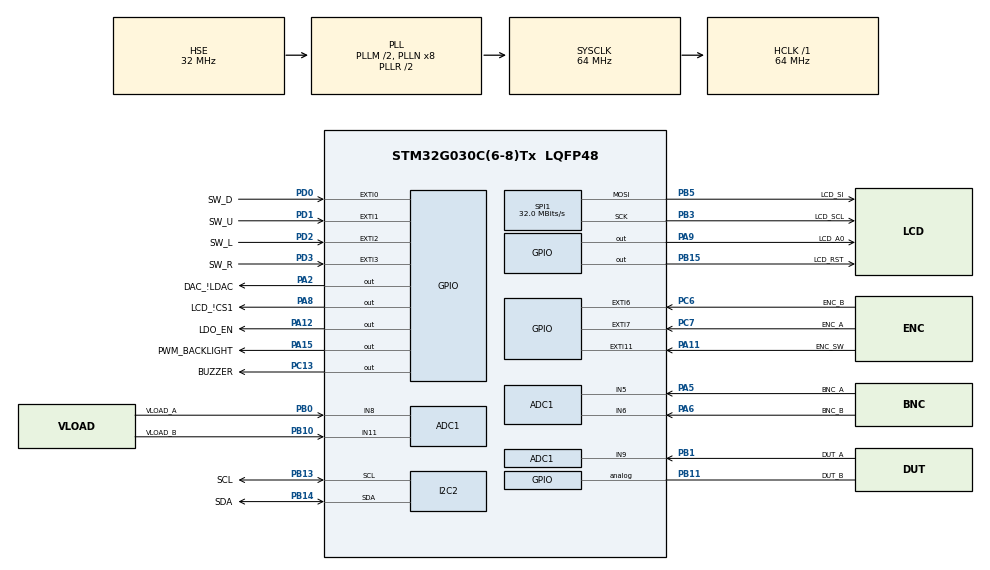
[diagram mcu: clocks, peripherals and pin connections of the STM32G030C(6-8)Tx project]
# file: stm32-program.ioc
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ADC1.Channel-1\#ChannelRegularConversion=ADC_CHANNEL_5
ADC1.ContinuousConvMode=ENABLE
ADC1.NbrOfConversionFlag=1
ADC1.Rank-1\#ChannelRegularConversion=1
ADC1.SamplingTime-1\#ChannelRegularConversion=ADC_SAMPLINGTIME_COMMON_1
ADC1.SelectedChannel=ADC_CHANNEL_5|ADC_CHANNEL_6|ADC_CHANNEL_8|ADC_CHANNEL_9|ADC_CHANNEL_11
ADC1.master=1
I2C2.Timing=0x10B17DB5
Mcu.Family=STM32G0
Mcu.Name=STM32G030C(6-8)Tx
Mcu.Package=LQFP48
NVIC.ADC1_IRQn=true\:0\:0\:false\:false\:true\:true\:true\:true
NVIC.EXTI0_1_IRQn=true\:0\:0\:false\:false\:true\:true\:true\:true
NVIC.EXTI2_3_IRQn=true\:0\:0\:false\:false\:true\:true\:true\:true
NVIC.EXTI4_15_IRQn=true\:0\:0\:false\:false\:true\:true\:true\:true
NVIC.I2C2_IRQn=true\:0\:0\:false\:false\:true\:true\:true\:true
NVIC.SPI1_IRQn=true\:0\:0\:false\:false\:true\:true\:true\:true
PA11\ [PA9].GPIO_Label=ENC_SW
PA11\ [PA9].GPIO_ModeDefaultEXTI=GPIO_MODE_IT_FALLING
PA11\ [PA9].GPIO_PuPd=GPIO_PULLUP
PA11\ [PA9].Signal=GPXTI11
PA12\ [PA10].GPIO_Label=LDO_EN
PA12\ [PA10].Signal=GPIO_Output
PA13.GPIO_Label=SWDIO
PA13.Mode=Serial_Wire
PA13.Signal=SYS_SWDIO
PA14-BOOT0.GPIO_Label=SWCLK
PA14-BOOT0.Mode=Serial_Wire
PA14-BOOT0.Signal=SYS_SWCLK
PA15.GPIO_Label=PWM_BACKLIGHT
PA15.Signal=GPIO_Output
PA2.GPIO_Label=DAC_\!LDAC
PA2.Signal=GPIO_Output
PA5.GPIO_Label=BNC_A
PA5.Signal=SharedAnalog_PA5
PA6.GPIO_Label=BNC_B
PA6.Signal=SharedAnalog_PA6
PA8.GPIO_Label=LCD_\!CS1
PA8.Signal=GPIO_Output
PA9.GPIO_Label=LCD_A0
PA9.Signal=GPIO_Output
PB0.GPIO_Label=VLOAD_A
PB0.Signal=SharedAnalog_PB0
PB1.GPIO_Label=DUT_A
PB1.Signal=SharedAnalog_PB1
PB10.GPIO_Label=VLOAD_B
PB10.Signal=SharedAnalog_PB10
PB11.GPIO_Label=DUT_B
PB11.Signal=SharedAnalog_PB11
PB13.GPIO_Label=SCL
PB13.Mode=I2C
PB13.Signal=I2C2_SCL
PB14.GPIO_Label=SDA
PB14.Mode=I2C
PB14.Signal=I2C2_SDA
PB15.GPIO_Label=LCD_RST
PB15.Signal=GPIO_Output
PB3.GPIO_Label=LCD_SCL
PB3.Mode=TX_Only_Simplex_Unidirect_Master
PB3.Signal=SPI1_SCK
PB5.GPIO_Label=LCD_SI
PB5.Mode=TX_Only_Simplex_Unidirect_Master
PB5.Signal=SPI1_MOSI
PC13.GPIO_Label=BUZZER
PC13.Signal=GPIO_Output
PC6.GPIO_Label=ENC_B
PC6.GPIO_ModeDefaultEXTI=GPIO_MODE_IT_FALLING
PC6.Signal=GPXTI6
PC7.GPIO_Label=ENC_A
PC7.GPIO_ModeDefaultEXTI=GPIO_MODE_IT_FALLING
PC7.Signal=GPXTI7
PD0.GPIO_Label=SW_D
PD0.GPIO_ModeDefaultEXTI=GPIO_MODE_IT_FALLING
PD0.GPIO_PuPd=GPIO_PULLUP
PD0.Signal=GPXTI0
PD1.GPIO_Label=SW_U
PD1.GPIO_ModeDefaultEXTI=GPIO_MODE_IT_FALLING
PD1.GPIO_PuPd=GPIO_PULLUP
PD1.Signal=GPXTI1
PD2.GPIO_Label=SW_L
PD2.GPIO_ModeDefaultEXTI=GPIO_MODE_IT_FALLING
PD2.GPIO_PuPd=GPIO_PULLUP
PD2.Signal=GPXTI2
PD3.GPIO_Label=SW_R
PD3.GPIO_ModeDefaultEXTI=GPIO_MODE_IT_FALLING
PD3.GPIO_PuPd=GPIO_PULLUP
PD3.Signal=GPXTI3
PF0-OSC_IN\ (PF0).GPIO_Label=OSC_IN
PF0-OSC_IN\ (PF0).Mode=HSE-External-Oscillator
PF0-OSC_IN\ (PF0).Signal=RCC_OSC_IN
PF1-OSC_OUT\ (PF1).GPIO_Label=OSC_OUT
PF1-OSC_OUT\ (PF1).Mode=HSE-External-Oscillator
PF1-OSC_OUT\ (PF1).Signal=RCC_OSC_OUT
ProjectManager.HeapSize=0x200
ProjectManager.StackSize=0x400
ProjectManager.TargetToolchain=STM32CubeIDE
RCC.ADCFreq_Value=64000000
RCC.AHBFreq_Value=64000000
RCC.CortexFreq_Value=64000000
RCC.EXTERNAL_CLOCK_VALUE=12288000
RCC.EnbaleCSS=true
RCC.HCLKFreq_Value=64000000
RCC.HSE_VALUE=32000000
RCC.HSI_VALUE=16000000
RCC.LSE_VALUE=32768
RCC.PLLM=RCC_PLLM_DIV2
RCC.PLLSourceVirtual=RCC_PLLSOURCE_HSE
RCC.SYSCLKFreq_VALUE=64000000
RCC.SYSCLKSource=RCC_SYSCLKSOURCE_PLLCLK
RCC.VCOOutputFreq_Value=128000000
SH.SharedAnalog_PA5.0=GPIO_Analog
SH.SharedAnalog_PA5.1=ADC1_IN5,IN5
SH.SharedAnalog_PA6.0=GPIO_Analog
SH.SharedAnalog_PA6.1=ADC1_IN6,IN6
SH.SharedAnalog_PB0.0=GPIO_Analog
SH.SharedAnalog_PB0.1=ADC1_IN8,IN8
SH.SharedAnalog_PB1.0=GPIO_Analog
SH.SharedAnalog_PB1.1=ADC1_IN9,IN9
SH.SharedAnalog_PB10.0=GPIO_Analog
SH.SharedAnalog_PB10.1=ADC1_IN11,IN11
SH.SharedAnalog_PB11.0=GPIO_Analog
SH.SharedAnalog_PB11.1=ADC1_IN15
SPI1.CalculateBaudRate=32.0 MBits/s
SPI1.Direction=SPI_DIRECTION_2LINES
SPI1.Mode=SPI_MODE_MASTER
SPI1.VirtualType=VM_MASTER
board=custom

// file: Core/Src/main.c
/* USER CODE BEGIN Header */
/**
  ******************************************************************************
  * @file           : main.c
  * @brief          : Main program body
  ******************************************************************************
  * @attention
  *
  * Copyright (c) 2025 STMicroelectronics.
  * All rights reserved.
  *
  * This software is licensed under terms that can be found in the LICENSE file
  * in the root directory of this software component.
  * If no LICENSE file comes with this software, it is provided AS-IS.
  *
  ******************************************************************************
  */
/* USER CODE END Header */
#include "main.h"

ADC_HandleTypeDef hadc1;

I2C_HandleTypeDef hi2c2;

SPI_HandleTypeDef hspi1;

void SystemClock_Config(void);
static void MX_GPIO_Init(void);
static void MX_I2C2_Init(void);
static void MX_ADC1_Init(void);
static void MX_SPI1_Init(void);

int main(void)
{

  /* MCU Configuration--------------------------------------------------------*/

  /* Reset of all peripherals, Initializes the Flash interface and the Systick. */
  HAL_Init();

  /* Configure the system clock */
  SystemClock_Config();

  /* Initialize all configured peripherals */
  MX_GPIO_Init();
  MX_I2C2_Init();
  MX_ADC1_Init();
  MX_SPI1_Init();

  /* Infinite loop */
  while (1)
  {

  }
}

void SystemClock_Config(void)
{
  RCC_OscInitTypeDef RCC_OscInitStruct = {0};
  RCC_ClkInitTypeDef RCC_ClkInitStruct = {0};

  /** Configure the main internal regulator output voltage
  */
  HAL_PWREx_ControlVoltageScaling(PWR_REGULATOR_VOLTAGE_SCALE1);

  /** Initializes the RCC Oscillators according to the specified parameters
  * in the RCC_OscInitTypeDef structure.
  */
  RCC_OscInitStruct.OscillatorType = RCC_OSCILLATORTYPE_HSE;
  RCC_OscInitStruct.HSEState = RCC_HSE_ON;
  RCC_OscInitStruct.PLL.PLLState = RCC_PLL_ON;
  RCC_OscInitStruct.PLL.PLLSource = RCC_PLLSOURCE_HSE;
  RCC_OscInitStruct.PLL.PLLM = RCC_PLLM_DIV2;
  RCC_OscInitStruct.PLL.PLLN = 8;
  RCC_OscInitStruct.PLL.PLLP = RCC_PLLP_DIV2;
  RCC_OscInitStruct.PLL.PLLR = RCC_PLLR_DIV2;
  if (HAL_RCC_OscConfig(&RCC_OscInitStruct) != HAL_OK)
  {
    Error_Handler();
  }

  /** Initializes the CPU, AHB and APB buses clocks
  */
  RCC_ClkInitStruct.ClockType = RCC_CLOCKTYPE_HCLK|RCC_CLOCKTYPE_SYSCLK
                              |RCC_CLOCKTYPE_PCLK1;
  RCC_ClkInitStruct.SYSCLKSource = RCC_SYSCLKSOURCE_PLLCLK;
  RCC_ClkInitStruct.AHBCLKDivider = RCC_SYSCLK_DIV1;
  RCC_ClkInitStruct.APB1CLKDivider = RCC_HCLK_DIV1;

  if (HAL_RCC_ClockConfig(&RCC_ClkInitStruct, FLASH_LATENCY_2) != HAL_OK)
  {
    Error_Handler();
  }

  /** Enables the Clock Security System
  */
  HAL_RCC_EnableCSS();
}

static void MX_ADC1_Init(void)
{

  ADC_ChannelConfTypeDef sConfig = {0};

  /** Configure the global features of the ADC (Clock, Resolution, Data Alignment and number of conversion)
  */
  hadc1.Instance = ADC1;
  hadc1.Init.ClockPrescaler = ADC_CLOCK_SYNC_PCLK_DIV2;
  hadc1.Init.Resolution = ADC_RESOLUTION_12B;
  hadc1.Init.DataAlign = ADC_DATAALIGN_RIGHT;
  hadc1.Init.ScanConvMode = ADC_SCAN_DISABLE;
  hadc1.Init.EOCSelection = ADC_EOC_SINGLE_CONV;
  hadc1.Init.LowPowerAutoWait = DISABLE;
  hadc1.Init.LowPowerAutoPowerOff = DISABLE;
  hadc1.Init.ContinuousConvMode = ENABLE;
  hadc1.Init.NbrOfConversion = 1;
  hadc1.Init.ExternalTrigConv = ADC_SOFTWARE_START;
  hadc1.Init.ExternalTrigConvEdge = ADC_EXTERNALTRIGCONVEDGE_NONE;
  hadc1.Init.DMAContinuousRequests = DISABLE;
  hadc1.Init.Overrun = ADC_OVR_DATA_PRESERVED;
  hadc1.Init.SamplingTimeCommon1 = ADC_SAMPLETIME_1CYCLE_5;
  hadc1.Init.SamplingTimeCommon2 = ADC_SAMPLETIME_1CYCLE_5;
  hadc1.Init.OversamplingMode = DISABLE;
  hadc1.Init.TriggerFrequencyMode = ADC_TRIGGER_FREQ_HIGH;
  if (HAL_ADC_Init(&hadc1) != HAL_OK)
  {
    Error_Handler();
  }

  /** Configure Regular Channel
  */
  sConfig.Channel = ADC_CHANNEL_5;
  sConfig.Rank = ADC_REGULAR_RANK_1;
  sConfig.SamplingTime = ADC_SAMPLINGTIME_COMMON_1;
  if (HAL_ADC_ConfigChannel(&hadc1, &sConfig) != HAL_OK)
  {
    Error_Handler();
  }

}

static void MX_I2C2_Init(void)
{

  hi2c2.Instance = I2C2;
  hi2c2.Init.Timing = 0x10B17DB5;
  hi2c2.Init.OwnAddress1 = 0;
  hi2c2.Init.AddressingMode = I2C_ADDRESSINGMODE_7BIT;
  hi2c2.Init.DualAddressMode = I2C_DUALADDRESS_DISABLE;
  hi2c2.Init.OwnAddress2 = 0;
  hi2c2.Init.OwnAddress2Masks = I2C_OA2_NOMASK;
  hi2c2.Init.GeneralCallMode = I2C_GENERALCALL_DISABLE;
  hi2c2.Init.NoStretchMode = I2C_NOSTRETCH_DISABLE;
  if (HAL_I2C_Init(&hi2c2) != HAL_OK)
  {
    Error_Handler();
  }

  /** Configure Analogue filter
  */
  if (HAL_I2CEx_ConfigAnalogFilter(&hi2c2, I2C_ANALOGFILTER_ENABLE) != HAL_OK)
  {
    Error_Handler();
  }

  /** Configure Digital filter
  */
  if (HAL_I2CEx_ConfigDigitalFilter(&hi2c2, 0) != HAL_OK)
  {
    Error_Handler();
  }

}

static void MX_SPI1_Init(void)
{

  /* SPI1 parameter configuration*/
  hspi1.Instance = SPI1;
  hspi1.Init.Mode = SPI_MODE_MASTER;
  hspi1.Init.Direction = SPI_DIRECTION_2LINES;
  hspi1.Init.DataSize = SPI_DATASIZE_8BIT;
  hspi1.Init.CLKPolarity = SPI_POLARITY_LOW;
  hspi1.Init.CLKPhase = SPI_PHASE_1EDGE;
  hspi1.Init.NSS = SPI_NSS_SOFT;
  hspi1.Init.BaudRatePrescaler = SPI_BAUDRATEPRESCALER_2;
  hspi1.Init.FirstBit = SPI_FIRSTBIT_MSB;
  hspi1.Init.TIMode = SPI_TIMODE_DISABLE;
  hspi1.Init.CRCCalculation = SPI_CRCCALCULATION_DISABLE;
  hspi1.Init.CRCPolynomial = 7;
  hspi1.Init.CRCLength = SPI_CRC_LENGTH_DATASIZE;
  hspi1.Init.NSSPMode = SPI_NSS_PULSE_ENABLE;
  if (HAL_SPI_Init(&hspi1) != HAL_OK)
  {
    Error_Handler();
  }

}

static void MX_GPIO_Init(void)
{
  GPIO_InitTypeDef GPIO_InitStruct = {0};

  /* GPIO Ports Clock Enable */
  __HAL_RCC_GPIOC_CLK_ENABLE();
  __HAL_RCC_GPIOF_CLK_ENABLE();
  __HAL_RCC_GPIOA_CLK_ENABLE();
  __HAL_RCC_GPIOB_CLK_ENABLE();
  __HAL_RCC_GPIOD_CLK_ENABLE();

  /*Configure GPIO pin Output Level */
  HAL_GPIO_WritePin(BUZZER_GPIO_Port, BUZZER_Pin, GPIO_PIN_RESET);

  /*Configure GPIO pin Output Level */
  HAL_GPIO_WritePin(GPIOA, DAC__LDAC_Pin|LCD__CS1_Pin|LCD_A0_Pin|LDO_EN_Pin
                          |PWM_BACKLIGHT_Pin, GPIO_PIN_RESET);

  /*Configure GPIO pin Output Level */
  HAL_GPIO_WritePin(LCD_RST_GPIO_Port, LCD_RST_Pin, GPIO_PIN_RESET);

  /*Configure GPIO pin : BUZZER_Pin */
  GPIO_InitStruct.Pin = BUZZER_Pin;
  GPIO_InitStruct.Mode = GPIO_MODE_OUTPUT_PP;
  GPIO_InitStruct.Pull = GPIO_NOPULL;
  GPIO_InitStruct.Speed = GPIO_SPEED_FREQ_LOW;
  HAL_GPIO_Init(BUZZER_GPIO_Port, &GPIO_InitStruct);

  /*Configure GPIO pins : DAC__LDAC_Pin LCD__CS1_Pin LCD_A0_Pin LDO_EN_Pin
                           PWM_BACKLIGHT_Pin */
  GPIO_InitStruct.Pin = DAC__LDAC_Pin|LCD__CS1_Pin|LCD_A0_Pin|LDO_EN_Pin
                          |PWM_BACKLIGHT_Pin;
  GPIO_InitStruct.Mode = GPIO_MODE_OUTPUT_PP;
  GPIO_InitStruct.Pull = GPIO_NOPULL;
  GPIO_InitStruct.Speed = GPIO_SPEED_FREQ_LOW;
  HAL_GPIO_Init(GPIOA, &GPIO_InitStruct);

  /*Configure GPIO pin : LCD_RST_Pin */
  GPIO_InitStruct.Pin = LCD_RST_Pin;
  GPIO_InitStruct.Mode = GPIO_MODE_OUTPUT_PP;
  GPIO_InitStruct.Pull = GPIO_NOPULL;
  GPIO_InitStruct.Speed = GPIO_SPEED_FREQ_LOW;
  HAL_GPIO_Init(LCD_RST_GPIO_Port, &GPIO_InitStruct);

  /*Configure GPIO pins : ENC_B_Pin ENC_A_Pin */
  GPIO_InitStruct.Pin = ENC_B_Pin|ENC_A_Pin;
  GPIO_InitStruct.Mode = GPIO_MODE_IT_FALLING;
  GPIO_InitStruct.Pull = GPIO_NOPULL;
  HAL_GPIO_Init(GPIOC, &GPIO_InitStruct);

  /*Configure GPIO pin : ENC_SW_Pin */
  GPIO_InitStruct.Pin = ENC_SW_Pin;
  GPIO_InitStruct.Mode = GPIO_MODE_IT_FALLING;
  GPIO_InitStruct.Pull = GPIO_PULLUP;
  HAL_GPIO_Init(ENC_SW_GPIO_Port, &GPIO_InitStruct);

  /*Configure GPIO pins : SW_D_Pin SW_U_Pin SW_L_Pin SW_R_Pin */
  GPIO_InitStruct.Pin = SW_D_Pin|SW_U_Pin|SW_L_Pin|SW_R_Pin;
  GPIO_InitStruct.Mode = GPIO_MODE_IT_FALLING;
  GPIO_InitStruct.Pull = GPIO_PULLUP;
  HAL_GPIO_Init(GPIOD, &GPIO_InitStruct);

  /* EXTI interrupt init*/
  HAL_NVIC_SetPriority(EXTI0_1_IRQn, 0, 0);
  HAL_NVIC_EnableIRQ(EXTI0_1_IRQn);

  HAL_NVIC_SetPriority(EXTI2_3_IRQn, 0, 0);
  HAL_NVIC_EnableIRQ(EXTI2_3_IRQn);

  HAL_NVIC_SetPriority(EXTI4_15_IRQn, 0, 0);
  HAL_NVIC_EnableIRQ(EXTI4_15_IRQn);

}

/* USER CODE BEGIN 4 */

static void HAL_GPIO_EXTI_Callback(uint16_t GPIO_Pin) {

}

/* USER CODE END 4 */

void Error_Handler(void)
{
  __disable_irq();
  while (1)
  {
  }
}
